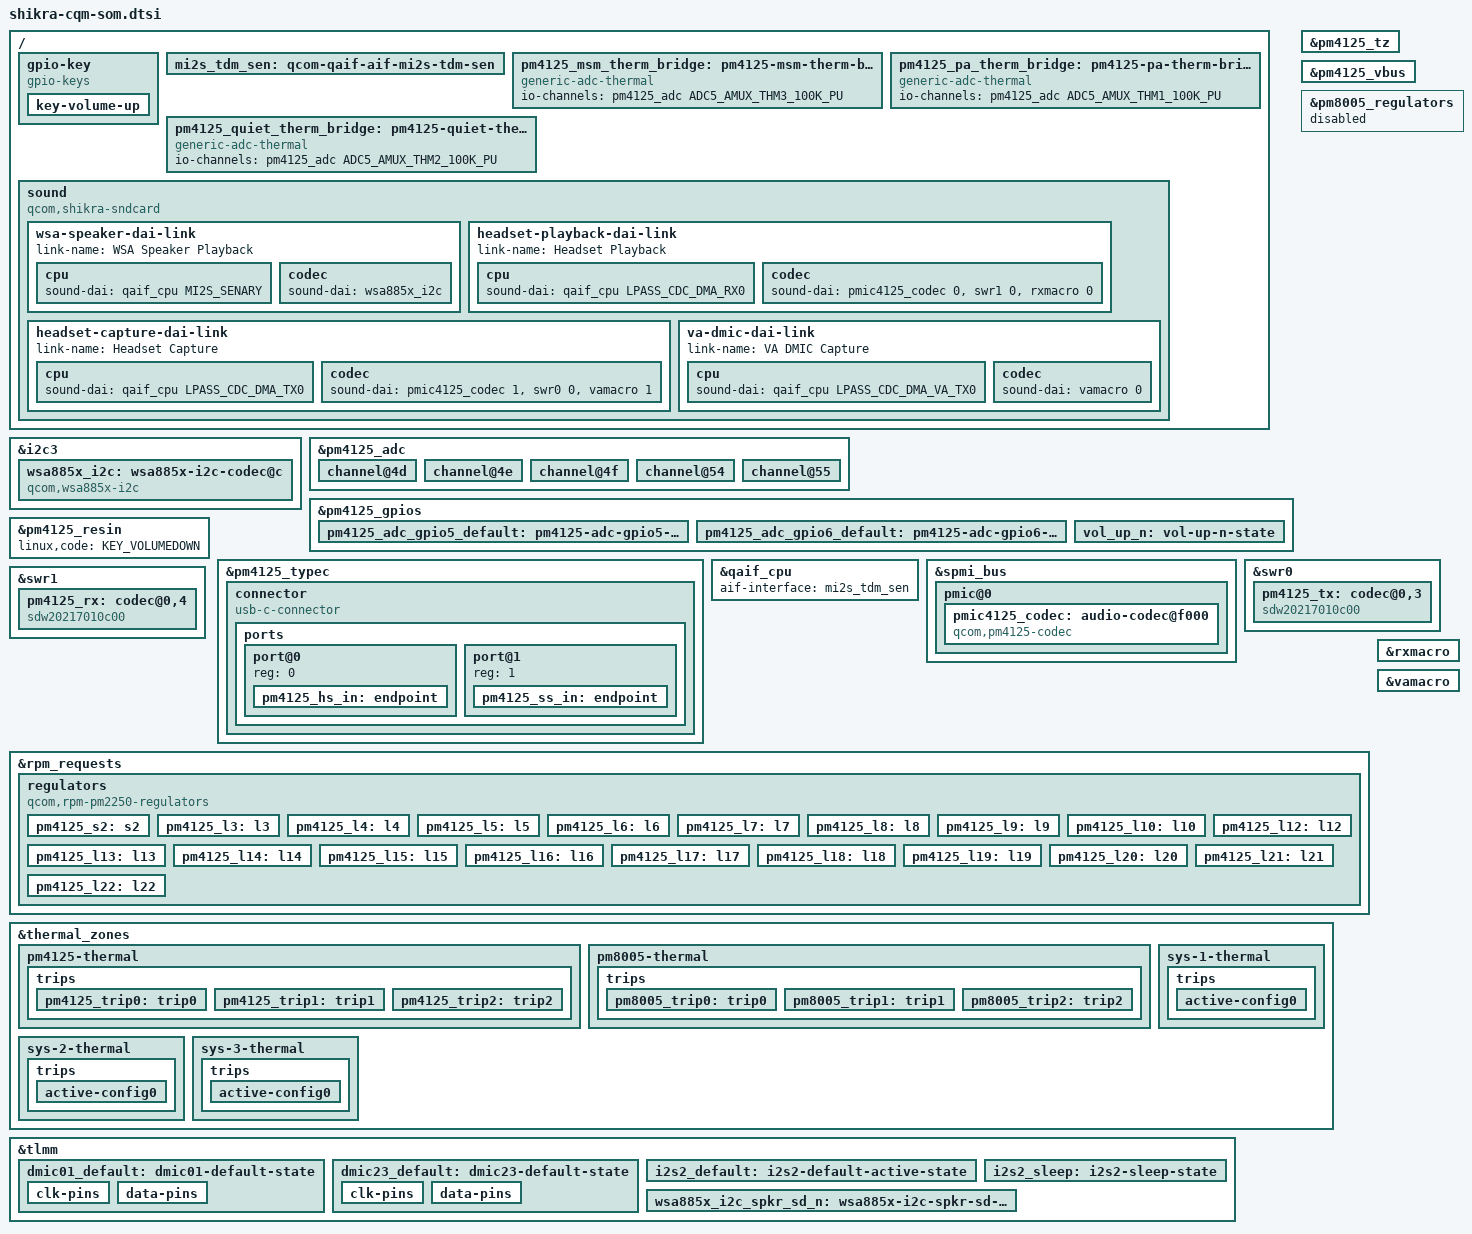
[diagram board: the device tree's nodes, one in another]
// SPDX-License-Identifier: BSD-3-Clause
/*
 * Copyright (c) Qualcomm Technologies, Inc. and/or its subsidiaries.
 */

#include <dt-bindings/gpio/gpio.h>
#include <dt-bindings/iio/qcom,spmi-vadc.h>
#include <dt-bindings/input/input.h>
#include <dt-bindings/pinctrl/qcom,pmic-gpio.h>
#include <dt-bindings/sound/qcom,lpass.h>

#include "shikra.dtsi"
#include "pm4125.dtsi"
#include "pm8005.dtsi"

/* Modem, Cocos + Kunlun PMIC */
/ {
	gpio-key {
		compatible = "gpio-keys";
		label = "gpio-keys";
		pinctrl-names = "default";
		pinctrl-0 = <&vol_up_n>;

		key-volume-up {
			label = "Volume Up";
			gpios = <&pm4125_gpios 9 GPIO_ACTIVE_LOW>;
			linux,input-type = <1>;
			linux,code = <KEY_VOLUMEUP>;
			wakeup-source;
			debounce-interval = <15>;
			linux,can-disable;
		};
	};

	mi2s_tdm_sen: qcom-qaif-aif-mi2s-tdm-sen {
		qcom,qaif-intf-dai-id = <34>;
		qcom,qaif-aif-sync-mode = <1>;
		qcom,qaif-aif-sync-src = <1>;
		qcom,qaif-aif-invert-sync = <0>;
		qcom,qaif-aif-sync-delay = <1>;
		qcom,qaif-aif-slot-width-rx = <32>;
		qcom,qaif-aif-slot-width-tx = <32>;
		qcom,qaif-aif-sample-width-rx = <16>;
		qcom,qaif-aif-sample-width-tx = <16>;
		qcom,qaif-aif-slot-en-rx-mask = <0x3>;
		qcom,qaif-aif-slot-en-tx-mask = <0x3>;
		qcom,qaif-aif-loopback-en = <0>;
		qcom,qaif-aif-ctrl-data-oe = <1>;
		qcom,qaif-aif-lane-config = <1 1>, <1 0>;
		qcom,qaif-aif-mono-mode-tx = <0>;
		qcom,qaif-aif-mono-mode-rx = <0>;
		qcom,qaif-aif-full-cycle-en = <0>;
		qcom,qaif-aif-bits-per-lane = <2>;
	};

	pm4125_msm_therm_bridge: pm4125-msm-therm-bridge {
		compatible = "generic-adc-thermal";
		io-channels = <&pm4125_adc ADC5_AMUX_THM3_100K_PU>;
		io-channel-names = "sensor-channel";
		#thermal-sensor-cells = <0>;
	};

	pm4125_pa_therm_bridge: pm4125-pa-therm-bridge {
		compatible = "generic-adc-thermal";
		io-channels = <&pm4125_adc ADC5_AMUX_THM1_100K_PU>;
		io-channel-names = "sensor-channel";
		#thermal-sensor-cells = <0>;
	};

	pm4125_quiet_therm_bridge: pm4125-quiet-therm-bridge {
		compatible = "generic-adc-thermal";
		io-channels = <&pm4125_adc ADC5_AMUX_THM2_100K_PU>;
		io-channel-names = "sensor-channel";
		#thermal-sensor-cells = <0>;
	};

	sound: sound {
		compatible = "qcom,shikra-sndcard";
		model = "Shikra-CQM-EVK";

		pinctrl-0 = <&i2s2_default>;
		pinctrl-1 = <&i2s2_sleep>;
		pinctrl-names = "default", "sleep";

		wsa-speaker-dai-link {
			link-name = "WSA Speaker Playback";

			cpu {
				sound-dai = <&qaif_cpu MI2S_SENARY>;
			};

			codec {
				sound-dai = <&wsa885x_i2c>;
			};
		};

		headset-playback-dai-link {
			link-name = "Headset Playback";

			cpu {
				sound-dai = <&qaif_cpu LPASS_CDC_DMA_RX0>;
			};

			codec {
				sound-dai = <&pmic4125_codec 0>,
					    <&swr1 0>,
					    <&rxmacro 0>;
			};
		};

		headset-capture-dai-link {
			link-name = "Headset Capture";

			cpu {
				sound-dai = <&qaif_cpu LPASS_CDC_DMA_TX0>;
			};

			codec {
				sound-dai = <&pmic4125_codec 1>,
					    <&swr0 0>,
					    <&vamacro 1>;
			};
		};

		va-dmic-dai-link {
			link-name = "VA DMIC Capture";

			cpu {
				sound-dai = <&qaif_cpu LPASS_CDC_DMA_VA_TX0>;
			};

			codec {
				sound-dai = <&vamacro 0>;
			};
		};
	};
};

&i2c3 {
	status = "okay";

	wsa885x_i2c: wsa885x-i2c-codec@c {
		compatible = "qcom,wsa885x-i2c";
		reg = <0x0c>;

		pinctrl-names = "default";
		pinctrl-0 = <&wsa885x_i2c_spkr_sd_n>;

		interrupt-gpios = <&tlmm 77 GPIO_ACTIVE_HIGH>;
		powerdown-gpios = <&tlmm 2 GPIO_ACTIVE_LOW>;
		vdd-1p8-supply = <&pm4125_l15>;
		vdd-io-supply = <&pm4125_l15>;
		qcom,battery_config = <2>;

		wsa885x-init-table =
			<0x8470 0x2   /* DIG_CTRL0_CDC_RXTX_FSCNT_CTL - FS_CNT_CLR(1) */
			0x8470 0x0   /* DIG_CTRL0_CDC_RXTX_FSCNT_CTL - FS_CNT_CLR(0) */
			0x8470 0x1   /* DIG_CTRL0_CDC_RXTX_FSCNT_CTL - FS_CNT_EN(1) */
			0x0004 0x1   /* SMP_AMP_CTRL_STEREO_CMT_GRP_MASK - CMT_GRP_MASK(1) */
			0x8602 0x60  /* CDC_RX0_RX_PATH_CFG1 - HPF_EN(0) */
			0x8622 0x60  /* CDC_RX1_RX_PATH_CFG1 - HPF_EN(0) */
			0x8458 0x79  /* PANDEIRO_DIG_CTRL0_VBAT_THRM_FLT_CTL - VBAT_COEF_SEL */
			0x810B 0xD9  /* PANDEIRO_ANA_TOP_SPK_TOP_PWRSTG_CH1_TUNE3 */
			0x8111 0xD9  /* PANDEIRO_ANA_TOP_SPK_TOP_PWRSTG_CH2_TUNE3 */
			0x813C 0x08  /* SPK_TOP_COMMON_CTRL4 - override_ctl*/
			0x8102 0x04  /* PANDEIROI2S.TOP.PANDEIRO_ANA_TOP.SPK_TOP_COMMON_CTRL2.LDO_PROG */
			0x811C 0x29  /* PANDEIROI2S.TOP.PANDEIRO_ANA_TOP.SPK_TOP_LF_CH1_CTRL11.PHASE90(Add 90 degree phase shift between PWM clock of CH1 and CH2.) */
			0x811D 0x40  /* PANDEIRO_ANA_TOP_SPK_TOP_LF_CH1_TUNE1  - HIZ_DELAY_PROG*/
			0x8129 0x40  /* PANDEIRO_ANA_TOP_SPK_TOP_LF_CH2_TUNE1  - HIZ_DELAY_PROG*/
			0x811A 0x80  /* PANDEIRO_ANA_TOP_SPK_TOP_LF_CH1_CTRL9 - OCP_CLIP_T_CTRL_EXT */
			0x8126 0x80  /* PANDEIRO_ANA_TOP_SPK_TOP_LF_CH2_CTRL9 -  OCP_CLIP_T_CTRL_EXT */
			0x8103 0x6   /* PANDEIRO_ANA_TOP_SPK_TOP_COMMON_TUNE1 - GAIN_TUNE */
			0x80CA 0x85  /* PANDEIRO_ANA_TOP_IVSENSE_ADC_MODE_CTL2 - SPARE_BITS_0(Sets LDO to 1.6V) */
			0x80CB 0xE   /* PANDEIRO_ANA_TOP_IVSENSE_ADC_MODE_CTL3 - ADC_VREF_VCTL_I(Sets VREF_I to 1.35V) */
			0x80CC 0xC   /* PANDEIRO_ANA_TOP_IVSENSE_ADC_REF_CTL - ADC_VREF_VCTL_V(Sets VREF_V to 1.35V) */
			0x80D0 0x80 /* PANDEIRO_ANA_TOP_IVSENSE_ADC_CDAC_CAL_CTL2 */
			0x80BA 0xC0 /* PANDEIROI2S.TOP.PANDEIRO_ANA_TOP.SPK_TOP_SPARE3(force the VDDSPK_LV_READY from analog to be high) */
			0x841C 0x4E /* PANDEIROI2S.TOP.PANDEIRO_DIG_CTRL0_PANDEIRO_DIG_CTRL0.CDC_CLK_CTL.FSM_INTP_CG_DISABLE */
			0x8435 0x47 /* PANDEIRO_DIG_CTRL0_PA1_FSM_CTL1 - SILENT_STATE_IVS_EN */
			0x86CE 0x09 /* PANDEIROI2S.TOP.CDC_CLSH_CDC_CLSH.V1P8_BP_CTL2.BP_CNT */
			0x8667 0x34 /* CDC_COMPANDER1_CTL7 - AGAIN_DELAY */
			0x800D 0x08>; /* PANDEIROI2S.TOP.PANDEIRO_ANA_TOP.PON_CKSK_CTL_0 */

			#sound-dai-cells = <0>;
	};
};

&pm4125_adc {
	pinctrl-0 = <&pm4125_adc_gpio5_default>, <&pm4125_adc_gpio6_default>;
	pinctrl-names = "default";
	status = "okay";

	channel@4d {
		reg = <ADC5_AMUX_THM1_100K_PU>;
		label = "pa_therm";
		qcom,ratiometric;
		qcom,hw-settle-time = <200>;
		qcom,pre-scaling = <1 1>;
	};

	channel@4e {
		reg = <ADC5_AMUX_THM2_100K_PU>;
		label = "quiet_therm";
		qcom,ratiometric;
		qcom,hw-settle-time = <200>;
		qcom,pre-scaling = <1 1>;
	};

	channel@4f {
		reg = <ADC5_AMUX_THM3_100K_PU>;
		label = "msm_therm";
		qcom,ratiometric;
		qcom,hw-settle-time = <200>;
		qcom,pre-scaling = <1 1>;
	};

	channel@54 {
		reg = <ADC5_GPIO3_100K_PU>;
		label = "chgr_skin";
		qcom,ratiometric;
		qcom,hw-settle-time = <200>;
		qcom,pre-scaling = <1 1>;
	};

	channel@55 {
		reg = <ADC5_GPIO4_100K_PU>;
		label = "gnss_therm";
		qcom,ratiometric;
		qcom,hw-settle-time = <200>;
		qcom,pre-scaling = <1 1>;
	};
};

&pm4125_gpios {
	pm4125_adc_gpio5_default: pm4125-adc-gpio5-state {
		pins = "gpio5";
		function = PMIC_GPIO_FUNC_NORMAL;
		bias-high-impedance;
	};

	pm4125_adc_gpio6_default: pm4125-adc-gpio6-state {
		pins = "gpio6";
		function = PMIC_GPIO_FUNC_NORMAL;
		bias-high-impedance;
	};

	vol_up_n: vol-up-n-state {
		pins = "gpio9";
		function = PMIC_GPIO_FUNC_NORMAL;
		input-enable;
		bias-pull-up;
		power-source = <0>;
	};
};

&pm4125_resin {
	linux,code = <KEY_VOLUMEDOWN>;
	status = "okay";
};

&pm4125_typec {
	status = "okay";

	connector {
		compatible = "usb-c-connector";

		power-role = "dual";
		data-role = "dual";
		self-powered;

		typec-power-opmode = "default";
		pd-disable;

		ports {
			#address-cells = <1>;
			#size-cells = <0>;

			port@0 {
				reg = <0>;
				pm4125_hs_in: endpoint {
				};
			};

			port@1 {
				reg = <1>;
				pm4125_ss_in: endpoint {
				};
			};
		};
	};
};

&pm4125_tz {
	status = "okay";
};

&pm4125_vbus {
	regulator-min-microamp = <500000>;
	regulator-max-microamp = <500000>;
	status = "okay";
};

&pm8005_regulators {
	status = "disabled";
};

&qaif_cpu {
	aif-interface = <&mi2s_tdm_sen>;
	status = "okay";
};

&spmi_bus {
	pmic@0 {
		pmic4125_codec: audio-codec@f000 {
			compatible = "qcom,pm4125-codec";
			reg = <0xf000>;
			vdd-io-supply = <&pm4125_l15>;
			vdd-cp-supply = <&pm4125_s1>;
			vdd-pa-vpos-supply = <&pm4125_s1>;

			vdd-mic-bias-supply = <&pm4125_l22>;
			qcom,micbias1-microvolt = <1800000>;
			qcom,micbias2-microvolt = <1800000>;
			qcom,micbias3-microvolt = <1800000>;

			qcom,mbhc-buttons-vthreshold-microvolt = <75000 150000 237000 500000 500000 500000 500000 500000>;
			qcom,mbhc-headset-vthreshold-microvolt = <1700000>;
			qcom,mbhc-headphone-vthreshold-microvolt = <50000>;

			qcom,rx-device = <&pm4125_rx>;
			qcom,tx-device = <&pm4125_tx>;
			#sound-dai-cells = <1>;
		};
	};
};

&swr0 {
	status = "okay";

	pm4125_tx: codec@0,3 {
		compatible = "sdw20217010c00";
		reg = <0 3>;
		qcom,tx-port-mapping = <1 2 3>;
	};
};

&swr1 {
	status = "okay";

	pm4125_rx: codec@0,4 {
		compatible = "sdw20217010c00";
		reg = <0 4>;
		qcom,rx-port-mapping = <1 2 3 4 5>;
	};
};

&rpm_requests {
	regulators {
		compatible = "qcom,rpm-pm2250-regulators";

		pm4125_s2: s2 {
			regulator-min-microvolt = <1000000>;
			regulator-max-microvolt = <1200000>;
		};

		pm4125_l3: l3 {
			regulator-min-microvolt = <624000>;
			regulator-max-microvolt = <650000>;
		};

		pm4125_l4: l4 {
			regulator-min-microvolt = <1800000>;
			regulator-max-microvolt = <2960000>;
		};

		pm4125_l5: l5 {
			regulator-min-microvolt = <1232000>;
			regulator-max-microvolt = <1304000>;
		};

		pm4125_l6: l6 {
			regulator-min-microvolt = <788000>;
			regulator-max-microvolt = <1050000>;
		};

		pm4125_l7: l7 {
			regulator-min-microvolt = <664000>;
			regulator-max-microvolt = <664000>;
		};

		pm4125_l8: l8 {
			regulator-min-microvolt = <928000>;
			regulator-max-microvolt = <1000000>;
		};

		pm4125_l9: l9 {
			regulator-min-microvolt = <875000>;
			regulator-max-microvolt = <1000000>;
		};

		pm4125_l10: l10 {
			regulator-min-microvolt = <1304000>;
			regulator-max-microvolt = <1304000>;
		};

		pm4125_l12: l12 {
			regulator-min-microvolt = <928000>;
			regulator-max-microvolt = <975000>;
		};

		pm4125_l13: l13 {
			regulator-min-microvolt = <1800000>;
			regulator-max-microvolt = <1800000>;
		};

		pm4125_l14: l14 {
			regulator-min-microvolt = <1800000>;
			regulator-max-microvolt = <1800000>;
		};

		pm4125_l15: l15 {
			regulator-min-microvolt = <1800000>;
			regulator-max-microvolt = <1800000>;
		};

		pm4125_l16: l16 {
			regulator-min-microvolt = <1800000>;
			regulator-max-microvolt = <1800000>;
		};

		pm4125_l17: l17 {
			regulator-min-microvolt = <3000000>;
			regulator-max-microvolt = <3544000>;
		};

		pm4125_l18: l18 {
			regulator-min-microvolt = <1800000>;
			regulator-max-microvolt = <2960000>;
		};

		pm4125_l19: l19 {
			regulator-min-microvolt = <1800000>;
			regulator-max-microvolt = <2960000>;
		};

		pm4125_l20: l20 {
			regulator-min-microvolt = <2952000>;
			regulator-max-microvolt = <2952000>;
		};

		pm4125_l21: l21 {
			regulator-min-microvolt = <3000000>;
			regulator-max-microvolt = <3056000>;
		};

		pm4125_l22: l22 {
			regulator-min-microvolt = <3304000>;
			regulator-max-microvolt = <3304000>;
		};
	};
};

&rxmacro {
	status = "okay";
};

&thermal_zones {
	pm4125-thermal {
		polling-delay-passive = <100>;
		polling-delay = <0>;
		thermal-sensors = <&pm4125_tz>;

		trips {
			pm4125_trip0: trip0 {
				temperature = <105000>;
				hysteresis = <0>;
				type = "passive";
			};

			pm4125_trip1: trip1 {
				temperature = <125000>;
				hysteresis = <0>;
				type = "hot";
			};

			pm4125_trip2: trip2 {
				temperature = <155000>;
				hysteresis = <0>;
				type = "critical";
			};
		};
	};

	pm8005-thermal {
		polling-delay-passive = <0>;
		polling-delay = <0>;
		thermal-sensors = <&pm8005_tz>;

		trips {
			pm8005_trip0: trip0 {
				temperature = <105000>;
				hysteresis = <0>;
				type = "passive";
			};

			pm8005_trip1: trip1 {
				temperature = <125000>;
				hysteresis = <0>;
				type = "passive";
			};

			pm8005_trip2: trip2 {
				temperature = <145000>;
				hysteresis = <0>;
				type = "passive";
			};
		};
	};

	sys-1-thermal {
		polling-delay-passive = <2000>;
		polling-delay = <0>;
		thermal-sensors = <&pm4125_pa_therm_bridge>;

		trips {
			active-config0 {
				temperature = <125000>;
				hysteresis = <1000>;
				type = "passive";
			};
		};
	};

	sys-2-thermal {
		polling-delay-passive = <2000>;
		polling-delay = <0>;
		thermal-sensors = <&pm4125_quiet_therm_bridge>;

		trips {
			active-config0 {
				temperature = <125000>;
				hysteresis = <1000>;
				type = "passive";
			};
		};
	};

	sys-3-thermal {
		polling-delay-passive = <2000>;
		polling-delay = <0>;
		thermal-sensors = <&pm4125_msm_therm_bridge>;

		trips {
			active-config0 {
				temperature = <125000>;
				hysteresis = <1000>;
				type = "passive";
			};
		};
	};
};

&tlmm {
	dmic01_default: dmic01-default-state {
		clk-pins {
			pins = "gpio96";
			function = "dmic";
			drive-strength = <8>;
			output-high;
		};

		data-pins {
			pins = "gpio97";
			function = "dmic";
			drive-strength = <8>;
			input-enable;
		};
	};

	dmic23_default: dmic23-default-state {
		clk-pins {
			pins = "gpio98";
			function = "dmic";
			drive-strength = <8>;
			output-high;
		};

		data-pins {
			pins = "gpio99";
			function = "dmic";
			drive-strength = <8>;
			input-enable;
		};
	};

	i2s2_default: i2s2-default-active-state {
		pins = "gpio100", "gpio101", "gpio102", "gpio103";
		function = "i2s2";
		drive-strength = <8>;
		bias-disable;
	};

	i2s2_sleep: i2s2-sleep-state {
		pins = "gpio100", "gpio101", "gpio102", "gpio103";
		function = "i2s2";
		drive-strength = <2>;
		bias-disable;
	};

	wsa885x_i2c_spkr_sd_n: wsa885x-i2c-spkr-sd-n-active-state {
		pins = "gpio2";
		function = "gpio";
		drive-strength = <16>;
		bias-disable;
		input-disable;
		output-enable;
	};
};

&vamacro {
	pinctrl-0 = <&dmic01_default>, <&dmic23_default>;
	pinctrl-names = "default";

	qcom,dmic-sample-rate = <4800000>;
	status = "okay";
};
